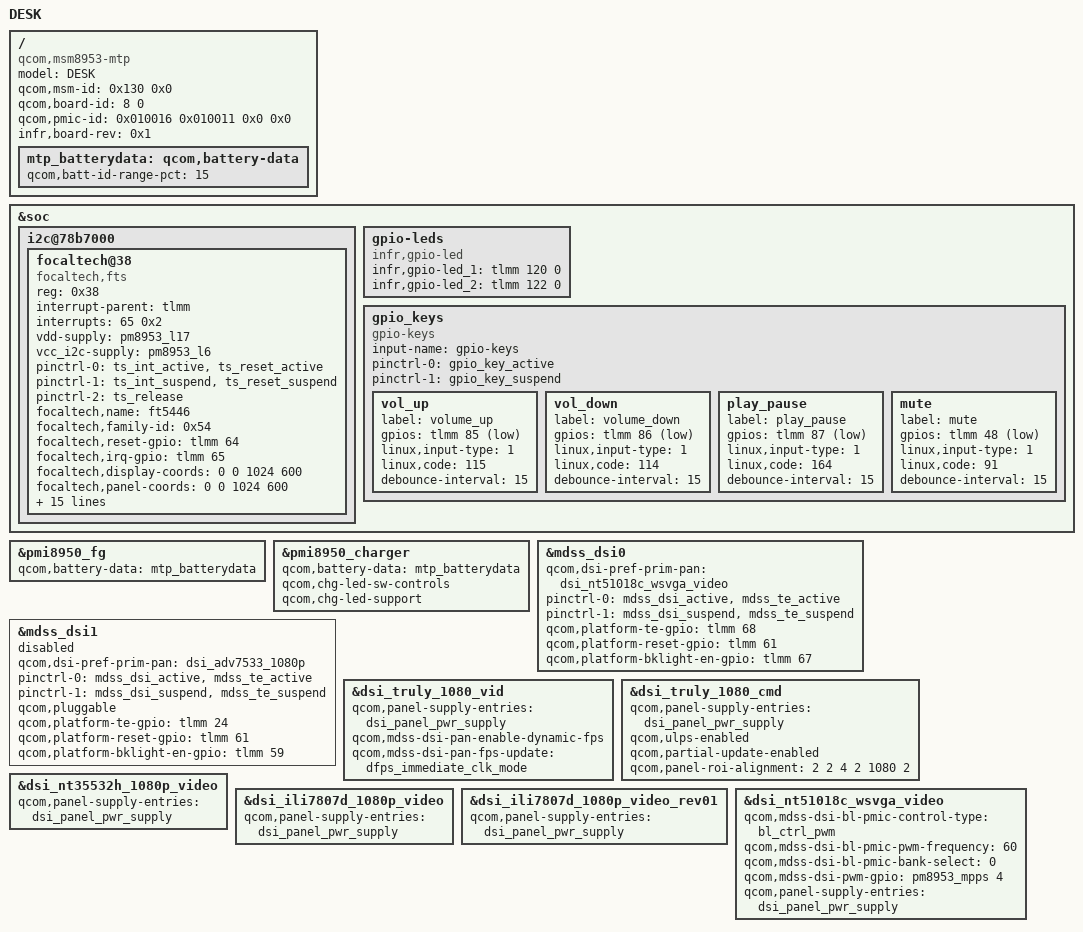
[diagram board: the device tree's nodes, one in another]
/*
 * Copyright (c) 2015-2017, The Linux Foundation. All rights reserved.
 *
 * This program is free software; you can redistribute it and/or modify
 * it under the terms of the GNU General Public License version 2 and
 * only version 2 as published by the Free Software Foundation.
 *
 * This program is distributed in the hope that it will be useful,
 * but WITHOUT ANY WARRANTY; without even the implied warranty of
 * MERCHANTABILITY or FITNESS FOR A PARTICULAR PURPOSE.  See the
 * GNU General Public License for more details.
 */

/dts-v1/;

#include "msm8953.dtsi"
#include "msm-pmi8950.dtsi"
#include "msm8953-mtp.dtsi"
#include "msm8953-pmi8950.dtsi"
#include "msm8953-camera-sensor-mtp.dtsi"

/ {
	model = "DESK";
	compatible = "qcom,msm8953-mtp", "qcom,msm8953", "qcom,mtp";
	qcom,msm-id = <0x130 0x0>;
//	qcom,pmic-id = <0x1000b 0x0 0x0 0x0>;
	qcom,board-id= <8 0>;
	qcom,pmic-id = <0x010016 0x010011 0x0 0x0>;
	infr,board-rev = <0x1>;
};

&soc {
//	i2c@78b6000 { /* BLSP1 QUP2 */
	i2c@78b7000 {
		focaltech@38 {
			compatible = "focaltech,fts";
			reg = <0x38>;
			interrupt-parent = <&tlmm>;
			interrupts = <65 0x2>;
			vdd-supply = <&pm8953_l17>;
			vcc_i2c-supply = <&pm8953_l6>;
			// pins used by touchscreen
			pinctrl-names = "pmx_ts_active","pmx_ts_suspend",
							"pmx_ts_release";
//							"pmx_ts_release","ts_ff";
			pinctrl-0 = <&ts_int_active &ts_reset_active>;
			pinctrl-1 = <&ts_int_suspend &ts_reset_suspend>;
			pinctrl-2 = <&ts_release>;
//			pinctrl-3 = <&ts_ff>;
			focaltech,name = "ft5446";
			focaltech,family-id = <0x54>;
			focaltech,reset-gpio = <&tlmm 64 0x0>;
			focaltech,irq-gpio = <&tlmm 65 0x2008>;
			focaltech,display-coords = <0 0 1024 600>;
			focaltech,panel-coords = <0 0 1024 600>;
			focaltech,no-force-update;
			focaltech,i2c-pull-up;
			focaltech,group-id = <1>;
			focaltech,hard-reset-delay-ms = <20>;
			focaltech,soft-reset-delay-ms = <200>;
			focaltech,num-max-touches = <5>;
			focaltech,fw-delay-aa-ms = <30>;
			focaltech,fw-delay-55-ms = <30>;
			focaltech,fw-upgrade-id1 = <0x79>;
			focaltech,fw-upgrade-id2 = <0x10>;
			focaltech,fw-delay-readid-ms = <10>;
			focaltech,fw-delay-era-flsh-ms = <2000>;
			focaltech,fw-auto-cal;
			focaltech,ignore-id-check;
			focaltech,resume-in-workqueue;
			//focaltech,fw-name = "FT5446_5.5inch_0x02_20170711_all.bin";
		};
	};
		gpio-leds {
			compatible = "infr,gpio-led";
			status = "okay";
			//pinctrl-names = "default";
			//pinctrl-0 = <&gpio_led_off>;
			infr,gpio-led_1 = <&tlmm 120 0>;
			infr,gpio-led_2 = <&tlmm 122 0>; 
			
		};


	gpio_keys {
		compatible = "gpio-keys";
		input-name = "gpio-keys";
		pinctrl-names = "tlmm_gpio_key_active","tlmm_gpio_key_suspend";
		pinctrl-0 = <&gpio_key_active>;
		pinctrl-1 = <&gpio_key_suspend>;

		vol_up {
			label = "volume_up";
			gpios = <&tlmm 85 0x1>;
			linux,input-type = <1>;
			linux,code = <115>;
			debounce-interval = <15>;
		};

		vol_down {
			label = "volume_down";
			gpios = <&tlmm 86 0x1>;
			linux,input-type = <1>;
			linux,code = <114>;
			debounce-interval = <15>;
		};

		play_pause {
			label = "play_pause";
			gpios = <&tlmm 87 0x1>;
			linux,input-type = <1>;
			linux,code = <164>;
			debounce-interval = <15>;
		};

		mute {
			label = "mute";
			gpios = <&tlmm 48 0x1>;
			linux,input-type = <1>;
			linux,code = <91>;
			debounce-interval = <15>;
		};

	};
};

/{
	mtp_batterydata: qcom,battery-data {
		qcom,batt-id-range-pct = <15>;
		#include "batterydata_MarkT_IFS700N_3000mAh.dtsi"
	};
};

&pmi8950_fg {
	qcom,battery-data = <&mtp_batterydata>;
};

&pmi8950_charger {
	qcom,battery-data = <&mtp_batterydata>;
	qcom,chg-led-sw-controls;
	qcom,chg-led-support;
//	qcom,external-typec;
//	qcom,typec-psy-name = "typec";
};


&mdss_dsi0 {
    qcom,dsi-pref-prim-pan = <&dsi_nt51018c_wsvga_video>;
    pinctrl-names = "mdss_default", "mdss_sleep";
    pinctrl-0 = <&mdss_dsi_active &mdss_te_active>;
    pinctrl-1 = <&mdss_dsi_suspend &mdss_te_suspend>;

    qcom,platform-te-gpio = <&tlmm 68 0>;
    qcom,platform-reset-gpio = <&tlmm 61 0>;
    qcom,platform-bklight-en-gpio = <&tlmm 67 0>;
};

&mdss_dsi1 {
    status = "disabled";
    qcom,dsi-pref-prim-pan = <&dsi_adv7533_1080p>;
    pinctrl-names = "mdss_default", "mdss_sleep";
    pinctrl-0 = <&mdss_dsi_active &mdss_te_active>;
    pinctrl-1 = <&mdss_dsi_suspend &mdss_te_suspend>;

    qcom,pluggable;
    qcom,platform-te-gpio = <&tlmm 24 0>;
    qcom,platform-reset-gpio = <&tlmm 61 0>;
    qcom,platform-bklight-en-gpio = <&tlmm 59 0>;
};

&dsi_truly_1080_vid {
    qcom,panel-supply-entries = <&dsi_panel_pwr_supply>;
    qcom,mdss-dsi-pan-enable-dynamic-fps;
    qcom,mdss-dsi-pan-fps-update = "dfps_immediate_clk_mode";
};

&dsi_truly_1080_cmd {
    qcom,panel-supply-entries = <&dsi_panel_pwr_supply>;
    qcom,ulps-enabled;
    qcom,partial-update-enabled;
    qcom,panel-roi-alignment = <2 2 4 2 1080 2>;
};

&dsi_nt35532h_1080p_video {
    qcom,panel-supply-entries = <&dsi_panel_pwr_supply>;
};

&dsi_ili7807d_1080p_video {
    qcom,panel-supply-entries = <&dsi_panel_pwr_supply>;
};

&dsi_ili7807d_1080p_video_rev01 {
    qcom,panel-supply-entries = <&dsi_panel_pwr_supply>;
};

&dsi_nt51018c_wsvga_video {
	
    qcom,mdss-dsi-bl-pmic-control-type = "bl_ctrl_pwm";
    qcom,mdss-dsi-bl-pmic-pwm-frequency = <60>;
    qcom,mdss-dsi-bl-pmic-bank-select = <0>; // need config choose pwm
    qcom,mdss-dsi-pwm-gpio = <&pm8953_mpps 4 0>;
    /*
	qcom,mdss-dsi-bl-pmic-control-type = "bl_ctrl_wled";
	*/
    qcom,panel-supply-entries = <&dsi_panel_pwr_supply>;
};
